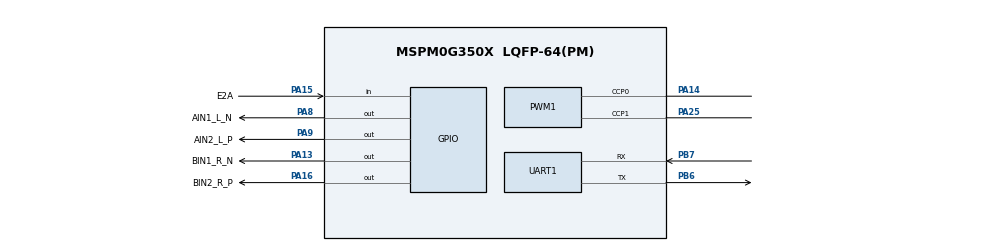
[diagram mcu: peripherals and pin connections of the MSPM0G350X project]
/**
 * @cliArgs --device "MSPM0G350X" --part "Default" --package "LQFP-64(PM)" --product "mspm0_sdk@2.04.00.06"
 * @versions {"tool":"1.22.0+3893"}
 */

/**
 * Import the modules used in this configuration.
 */
const Board         = scripting.addModule("/ti/driverlib/Board");
const GPIO          = scripting.addModule("/ti/driverlib/GPIO", {}, false);
const GPIO1         = GPIO.addInstance();
const GPIO2         = GPIO.addInstance();
const GPIO3         = GPIO.addInstance();
const GPIO4         = GPIO.addInstance();
const GPIO5         = GPIO.addInstance();
const GPIO6         = GPIO.addInstance();
const GPIO7         = GPIO.addInstance();
const GPIO8         = GPIO.addInstance();
const PWM           = scripting.addModule("/ti/driverlib/PWM", {}, false);
const PWM1          = PWM.addInstance();
const SYSCTL        = scripting.addModule("/ti/driverlib/SYSCTL");
const SYSTICK       = scripting.addModule("/ti/driverlib/SYSTICK");
const TIMER         = scripting.addModule("/ti/driverlib/TIMER", {}, false);
const TIMER1        = TIMER.addInstance();
const TIMER2        = TIMER.addInstance();
const TIMER3        = TIMER.addInstance();
const TIMER4        = TIMER.addInstance();
const UART          = scripting.addModule("/ti/driverlib/UART", {}, false);
const UART1         = UART.addInstance();
const ProjectConfig = scripting.addModule("/ti/project_config/ProjectConfig");

/**
 * Write custom configuration values to the imported modules.
 */
const divider6       = system.clockTree["PLL_CLK2X_DIV"];
divider6.divideValue = 4;

const divider7       = system.clockTree["PLL_PDIV"];
divider7.divideValue = 2;

const divider9       = system.clockTree["UDIV"];
divider9.divideValue = 2;

const multiplier2         = system.clockTree["PLL_QDIV"];
multiplier2.multiplyValue = 10;

const mux8       = system.clockTree["HSCLKMUX"];
mux8.inputSelect = "HSCLKMUX_SYSPLL2X";


GPIO1.$name                               = "MOTOR";
GPIO1.associatedPins.create(8);
GPIO1.associatedPins[0].assignedPin       = "8";
GPIO1.associatedPins[0].assignedPort      = "PORTA";
GPIO1.associatedPins[0].$name             = "AIN1_L_N";
GPIO1.associatedPins[0].pin.$assign       = "PA8";
GPIO1.associatedPins[1].assignedPin       = "9";
GPIO1.associatedPins[1].assignedPort      = "PORTA";
GPIO1.associatedPins[1].$name             = "AIN2_L_P";
GPIO1.associatedPins[1].pin.$assign       = "PA9";
GPIO1.associatedPins[2].assignedPin       = "13";
GPIO1.associatedPins[2].assignedPort      = "PORTA";
GPIO1.associatedPins[2].$name             = "BIN1_R_N";
GPIO1.associatedPins[2].pin.$assign       = "PA13";
GPIO1.associatedPins[3].assignedPin       = "16";
GPIO1.associatedPins[3].assignedPort      = "PORTA";
GPIO1.associatedPins[3].$name             = "BIN2_R_P";
GPIO1.associatedPins[3].pin.$assign       = "PA16";
GPIO1.associatedPins[4].assignedPin       = "12";
GPIO1.associatedPins[4].assignedPort      = "PORTA";
GPIO1.associatedPins[4].$name             = "E2B";
GPIO1.associatedPins[4].direction         = "INPUT";
GPIO1.associatedPins[4].polarity          = "RISE";
GPIO1.associatedPins[4].interruptPriority = "0";
GPIO1.associatedPins[4].internalResistor  = "PULL_DOWN";
GPIO1.associatedPins[4].interruptEn       = true;
GPIO1.associatedPins[5].assignedPort      = "PORTA";
GPIO1.associatedPins[5].assignedPin       = "15";
GPIO1.associatedPins[5].$name             = "E2A";
GPIO1.associatedPins[5].direction         = "INPUT";
GPIO1.associatedPins[5].polarity          = "RISE";
GPIO1.associatedPins[5].interruptPriority = "0";
GPIO1.associatedPins[5].internalResistor  = "PULL_DOWN";
GPIO1.associatedPins[5].interruptEn       = true;
GPIO1.associatedPins[5].ioStructure       = "SD";
GPIO1.associatedPins[5].pin.$assign       = "PA15";
GPIO1.associatedPins[6].assignedPort      = "PORTA";
GPIO1.associatedPins[6].assignedPin       = "21";
GPIO1.associatedPins[6].$name             = "E1A";
GPIO1.associatedPins[6].direction         = "INPUT";
GPIO1.associatedPins[6].polarity          = "RISE";
GPIO1.associatedPins[6].interruptPriority = "0";
GPIO1.associatedPins[6].internalResistor  = "PULL_DOWN";
GPIO1.associatedPins[6].interruptEn       = true;
GPIO1.associatedPins[6].ioStructure       = "SD";
GPIO1.associatedPins[7].assignedPort      = "PORTA";
GPIO1.associatedPins[7].assignedPin       = "22";
GPIO1.associatedPins[7].$name             = "E1B";
GPIO1.associatedPins[7].direction         = "INPUT";
GPIO1.associatedPins[7].polarity          = "RISE";
GPIO1.associatedPins[7].interruptPriority = "0";
GPIO1.associatedPins[7].internalResistor  = "PULL_DOWN";
GPIO1.associatedPins[7].interruptEn       = true;
GPIO1.associatedPins[7].ioStructure       = "SD";

GPIO2.port                          = "PORTA";
GPIO2.$name                         = "MPU";
GPIO2.associatedPins.create(2);
GPIO2.associatedPins[0].assignedPin = "0";
GPIO2.associatedPins[0].$name       = "MPU_SDA";
GPIO2.associatedPins[1].assignedPin = "1";
GPIO2.associatedPins[1].$name       = "MPU_SCL";

GPIO3.$name                              = "KEY";
GPIO3.associatedPins.create(3);
GPIO3.associatedPins[0].$name            = "KEY_1";
GPIO3.associatedPins[0].assignedPort     = "PORTB";
GPIO3.associatedPins[0].assignedPin      = "9";
GPIO3.associatedPins[0].internalResistor = "PULL_UP";
GPIO3.associatedPins[0].direction        = "INPUT";
GPIO3.associatedPins[1].internalResistor = "PULL_UP";
GPIO3.associatedPins[1].assignedPort     = "PORTB";
GPIO3.associatedPins[1].assignedPin      = "8";
GPIO3.associatedPins[1].$name            = "KEY_2";
GPIO3.associatedPins[1].direction        = "INPUT";
GPIO3.associatedPins[2].$name            = "KEY_3";
GPIO3.associatedPins[2].assignedPort     = "PORTA";
GPIO3.associatedPins[2].assignedPin      = "7";
GPIO3.associatedPins[2].internalResistor = "PULL_UP";
GPIO3.associatedPins[2].direction        = "INPUT";

GPIO4.port                                = "PORTB";
GPIO4.$name                               = "USOUND";
GPIO4.associatedPins.create(2);
GPIO4.associatedPins[0].$name             = "Trig";
GPIO4.associatedPins[0].assignedPin       = "19";
GPIO4.associatedPins[1].$name             = "Echo";
GPIO4.associatedPins[1].assignedPin       = "18";
GPIO4.associatedPins[1].direction         = "INPUT";
GPIO4.associatedPins[1].interruptEn       = true;
GPIO4.associatedPins[1].polarity          = "RISE_FALL";
GPIO4.associatedPins[1].internalResistor  = "PULL_DOWN";
GPIO4.associatedPins[1].interruptPriority = "0";

GPIO5.$name                         = "BUZ";
GPIO5.port                          = "PORTA";
GPIO5.associatedPins[0].$name       = "Buz";
GPIO5.associatedPins[0].assignedPin = "17";

GPIO6.$name                              = "LED";
GPIO6.associatedPins.create(3);
GPIO6.associatedPins[0].$name            = "LED1";
GPIO6.associatedPins[0].assignedPin      = "2";
GPIO6.associatedPins[0].assignedPort     = "PORTA";
GPIO6.associatedPins[0].internalResistor = "PULL_UP";
GPIO6.associatedPins[0].initialValue     = "SET";
GPIO6.associatedPins[1].$name            = "LED2";
GPIO6.associatedPins[1].assignedPort     = "PORTB";
GPIO6.associatedPins[1].assignedPin      = "24";
GPIO6.associatedPins[1].internalResistor = "PULL_UP";
GPIO6.associatedPins[1].initialValue     = "SET";
GPIO6.associatedPins[2].$name            = "LED3";
GPIO6.associatedPins[2].assignedPin      = "20";
GPIO6.associatedPins[2].assignedPort     = "PORTB";
GPIO6.associatedPins[2].internalResistor = "PULL_UP";
GPIO6.associatedPins[2].initialValue     = "SET";

GPIO7.$name                              = "Line";
GPIO7.port                               = "PORTA";
GPIO7.associatedPins.create(4);
GPIO7.associatedPins[0].$name            = "Right";
GPIO7.associatedPins[0].assignedPin      = "23";
GPIO7.associatedPins[0].internalResistor = "PULL_UP";
GPIO7.associatedPins[0].direction        = "INPUT";
GPIO7.associatedPins[1].$name            = "Middle1";
GPIO7.associatedPins[1].direction        = "INPUT";
GPIO7.associatedPins[1].assignedPin      = "26";
GPIO7.associatedPins[1].internalResistor = "PULL_UP";
GPIO7.associatedPins[2].$name            = "Middle2";
GPIO7.associatedPins[2].assignedPin      = "24";
GPIO7.associatedPins[2].internalResistor = "PULL_UP";
GPIO7.associatedPins[2].direction        = "INPUT";
GPIO7.associatedPins[3].$name            = "Left";
GPIO7.associatedPins[3].assignedPin      = "27";
GPIO7.associatedPins[3].internalResistor = "PULL_UP";
GPIO7.associatedPins[3].direction        = "INPUT";

GPIO8.$name                          = "GPIO_OLED";
GPIO8.associatedPins.create(2);
GPIO8.associatedPins[0].$name        = "PIN_SDA";
GPIO8.associatedPins[0].assignedPort = "PORTA";
GPIO8.associatedPins[0].assignedPin  = "28";
GPIO8.associatedPins[1].$name        = "PIN_SCL";
GPIO8.associatedPins[1].assignedPort = "PORTA";
GPIO8.associatedPins[1].assignedPin  = "31";

PWM1.$name                              = "PWM_Motor";
PWM1.timerStartTimer                    = true;
PWM1.pwmMode                            = "EDGE_ALIGN_UP";
PWM1.timerCount                         = 7200;
PWM1.peripheral.ccp0Pin.$assign         = "PA14";
PWM1.peripheral.ccp1Pin.$assign         = "PA25";
PWM1.PWM_CHANNEL_0.$name                = "ti_driverlib_pwm_PWMTimerCC0";
PWM1.PWM_CHANNEL_1.$name                = "ti_driverlib_pwm_PWMTimerCC1";
PWM1.ccp0PinConfig.$name                = "ti_driverlib_gpio_GPIOPinGeneric0";
PWM1.ccp0PinConfig.direction            = scripting.forceWrite("OUTPUT");
PWM1.ccp0PinConfig.hideOutputInversion  = scripting.forceWrite(false);
PWM1.ccp0PinConfig.onlyInternalResistor = scripting.forceWrite(false);
PWM1.ccp0PinConfig.passedPeripheralType = scripting.forceWrite("Digital");
PWM1.ccp1PinConfig.$name                = "ti_driverlib_gpio_GPIOPinGeneric1";
PWM1.ccp1PinConfig.direction            = scripting.forceWrite("OUTPUT");
PWM1.ccp1PinConfig.hideOutputInversion  = scripting.forceWrite(false);
PWM1.ccp1PinConfig.onlyInternalResistor = scripting.forceWrite(false);
PWM1.ccp1PinConfig.passedPeripheralType = scripting.forceWrite("Digital");

SYSCTL.forceDefaultClkConfig = true;
SYSCTL.clockTreeEn           = true;

SYSTICK.periodEnable  = true;
SYSTICK.systickEnable = true;
SYSTICK.period        = 32;

TIMER1.timerClkPrescale   = 32;
TIMER1.timerMode          = "ONE_SHOT_UP";
TIMER1.$name              = "TIMER_USOUND";
TIMER1.interrupts         = ["LOAD"];
TIMER1.timerPeriod        = "20ms";
TIMER1.interruptPriority  = "2";
TIMER1.peripheral.$assign = "TIMG0";

TIMER2.$name              = "TIMER_0";
TIMER2.timerMode          = "PERIODIC";
TIMER2.interrupts         = ["ZERO"];
TIMER2.timerStartTimer    = true;
TIMER2.timerClkPrescale   = 80;
TIMER2.interruptPriority  = "1";
TIMER2.timerPeriod        = "5ms";
TIMER2.peripheral.$assign = "TIMG7";

TIMER3.timerClkDiv        = 8;
TIMER3.timerMode          = "PERIODIC";
TIMER3.interrupts         = ["ZERO"];
TIMER3.timerStartTimer    = true;
TIMER3.timerPeriod        = "10 ms";
TIMER3.$name              = "TIMER_1";
TIMER3.timerClkPrescale   = 10;
TIMER3.interruptPriority  = "2";
TIMER3.peripheral.$assign = "TIMG6";

TIMER4.$name              = "TIMER_2";
TIMER4.timerClkPrescale   = 80;
TIMER4.timerPeriod        = "10 ms";
TIMER4.interrupts         = ["ZERO"];
TIMER4.interruptPriority  = "3";
TIMER4.timerStartTimer    = true;
TIMER4.timerMode          = "PERIODIC_UP";
TIMER4.peripheral.$assign = "TIMA0";

UART1.$name                            = "UART_1";
UART1.targetBaudRate                   = 115200;
UART1.enabledInterrupts                = ["RX"];
UART1.peripheral.rxPin.$assign         = "PB7";
UART1.peripheral.txPin.$assign         = "PB6";
UART1.txPinConfig.direction            = scripting.forceWrite("OUTPUT");
UART1.txPinConfig.hideOutputInversion  = scripting.forceWrite(false);
UART1.txPinConfig.onlyInternalResistor = scripting.forceWrite(false);
UART1.txPinConfig.passedPeripheralType = scripting.forceWrite("Digital");
UART1.txPinConfig.$name                = "ti_driverlib_gpio_GPIOPinGeneric4";
UART1.rxPinConfig.hideOutputInversion  = scripting.forceWrite(false);
UART1.rxPinConfig.onlyInternalResistor = scripting.forceWrite(false);
UART1.rxPinConfig.passedPeripheralType = scripting.forceWrite("Digital");
UART1.rxPinConfig.$name                = "ti_driverlib_gpio_GPIOPinGeneric5";

ProjectConfig.genLibDrivers = true;

/**
 * Pinmux solution for unlocked pins/peripherals. This ensures that minor changes to the automatic solver in a future
 * version of the tool will not impact the pinmux you originally saw.  These lines can be completely deleted in order to
 * re-solve from scratch.
 */
Board.peripheral.$suggestSolution            = "DEBUGSS";
Board.peripheral.swclkPin.$suggestSolution   = "PA20";
Board.peripheral.swdioPin.$suggestSolution   = "PA19";
GPIO1.associatedPins[4].pin.$suggestSolution = "PA12";
GPIO1.associatedPins[6].pin.$suggestSolution = "PA21";
GPIO1.associatedPins[7].pin.$suggestSolution = "PA22";
GPIO2.associatedPins[0].pin.$suggestSolution = "PA0";
GPIO2.associatedPins[1].pin.$suggestSolution = "PA1";
GPIO3.associatedPins[0].pin.$suggestSolution = "PB9";
GPIO3.associatedPins[1].pin.$suggestSolution = "PB8";
GPIO3.associatedPins[2].pin.$suggestSolution = "PA7";
GPIO4.associatedPins[0].pin.$suggestSolution = "PB19";
GPIO4.associatedPins[1].pin.$suggestSolution = "PB18";
GPIO5.associatedPins[0].pin.$suggestSolution = "PA17";
GPIO6.associatedPins[0].pin.$suggestSolution = "PA2";
GPIO6.associatedPins[1].pin.$suggestSolution = "PB24";
GPIO6.associatedPins[2].pin.$suggestSolution = "PB20";
GPIO7.associatedPins[0].pin.$suggestSolution = "PA23";
GPIO7.associatedPins[1].pin.$suggestSolution = "PA26";
GPIO7.associatedPins[2].pin.$suggestSolution = "PA24";
GPIO7.associatedPins[3].pin.$suggestSolution = "PA27";
GPIO8.associatedPins[0].pin.$suggestSolution = "PA28";
GPIO8.associatedPins[1].pin.$suggestSolution = "PA31";
PWM1.peripheral.$suggestSolution             = "TIMG12";
UART1.peripheral.$suggestSolution            = "UART1";
